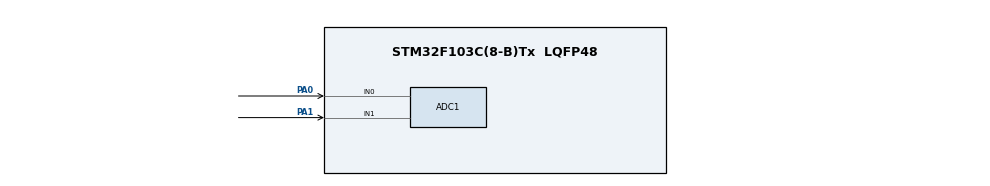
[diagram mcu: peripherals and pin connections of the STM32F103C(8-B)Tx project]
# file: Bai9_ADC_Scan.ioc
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Mcu.Family=STM32F1
NVIC.ADC1_2_IRQn=true\:0\:0\:false\:false\:true\:true\:true
Dma.ADC1.0.Instance=DMA1_Channel1
ADC1.Rank-0\#ChannelRegularConversion=1
ProjectManager.StackSize=0x400
PA0-WKUP.Signal=ADCx_IN0
PA13.Signal=SYS_JTMS-SWDIO
Dma.ADC1.0.PeriphDataAlignment=DMA_PDATAALIGN_HALFWORD
ProjectManager.TargetToolchain=MDK-ARM V5
Dma.ADC1.0.Mode=DMA_CIRCULAR
Dma.ADC1.0.Priority=DMA_PRIORITY_LOW
ADC1.Channel-1\#ChannelRegularConversion=ADC_CHANNEL_1
Dma.ADC1.0.Direction=DMA_PERIPH_TO_MEMORY
Dma.ADC1.0.MemDataAlignment=DMA_MDATAALIGN_HALFWORD
PA1.Signal=ADCx_IN1
ADC1.Channel-0\#ChannelRegularConversion=ADC_CHANNEL_0
board=custom
RCC.APB2Freq_Value=8000000
PA14.Mode=Serial_Wire
Dma.ADC1.0.PeriphInc=DMA_PINC_DISABLE
SH.ADCx_IN0.0=ADC1_IN0,IN0
ADC1.NbrOfConversion=2
PA13.Mode=Serial_Wire
Mcu.Name=STM32F103C(8-B)Tx
ADC1.SamplingTime-0\#ChannelRegularConversion=ADC_SAMPLETIME_239CYCLES_5
ADC1.SamplingTime-1\#ChannelRegularConversion=ADC_SAMPLETIME_239CYCLES_5
Mcu.Package=LQFP48
ADC1.master=1
ADC1.Rank-1\#ChannelRegularConversion=2
PA14.Signal=SYS_JTCK-SWCLK
Dma.ADC1.0.MemInc=DMA_MINC_ENABLE
ProjectManager.HeapSize=0x200
NVIC.PriorityGroup=NVIC_PRIORITYGROUP_4
ADC1.NbrOfConversionFlag=1
SH.ADCx_IN1.0=ADC1_IN1,IN1
NVIC.DMA1_Channel1_IRQn=true\:0\:0\:false\:false\:true\:false\:true
Dma.Request0=ADC1
RCC.APB1Freq_Value=8000000

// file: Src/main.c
/* USER CODE BEGIN Header */
/**
  ******************************************************************************
  * @file           : main.c
  * @brief          : Main program body
  ******************************************************************************
  * @attention
  *
  * <h2><center>&copy; Copyright (c) 2020 STMicroelectronics.
  * All rights reserved.</center></h2>
  *
  * This software component is licensed by ST under BSD 3-Clause license,
  * the "License"; You may not use this file except in compliance with the
  * License. You may obtain a copy of the License at:
  *                        opensource.org/licenses/BSD-3-Clause
  *
  ******************************************************************************
  */
/* USER CODE END Header */

#include "main.h"

ADC_HandleTypeDef hadc1;
DMA_HandleTypeDef hdma_adc1;

void SystemClock_Config(void);
static void MX_GPIO_Init(void);
static void MX_DMA_Init(void);
static void MX_ADC1_Init(void);
/* USER CODE BEGIN PFP */
uint16_t u16_ADCScanVal[2];
  /* NOTE : This function should not be modified. When the callback is needed,
            function HAL_ADC_ConvCpltCallback must be implemented in the user file.
   */
/* USER CODE END PFP */

int main(void)
{

  /* MCU Configuration--------------------------------------------------------*/

  /* Reset of all peripherals, Initializes the Flash interface and the Systick. */
  HAL_Init();

  /* Configure the system clock */
  SystemClock_Config();

  /* Initialize all configured peripherals */
  MX_GPIO_Init();
  MX_DMA_Init();
  MX_ADC1_Init();
  /* USER CODE BEGIN 2 */
	HAL_ADC_Start_DMA(&hadc1, (uint32_t*)u16_ADCScanVal, 2);
  /* USER CODE END 2 */

  /* Infinite loop */
  while (1)
  {

  }
}

void SystemClock_Config(void)
{
  RCC_OscInitTypeDef RCC_OscInitStruct = {0};
  RCC_ClkInitTypeDef RCC_ClkInitStruct = {0};
  RCC_PeriphCLKInitTypeDef PeriphClkInit = {0};

  /** Initializes the CPU, AHB and APB busses clocks
  */
  RCC_OscInitStruct.OscillatorType = RCC_OSCILLATORTYPE_HSI;
  RCC_OscInitStruct.HSIState = RCC_HSI_ON;
  RCC_OscInitStruct.HSICalibrationValue = RCC_HSICALIBRATION_DEFAULT;
  RCC_OscInitStruct.PLL.PLLState = RCC_PLL_NONE;
  if (HAL_RCC_OscConfig(&RCC_OscInitStruct) != HAL_OK)
  {
    Error_Handler();
  }
  /** Initializes the CPU, AHB and APB busses clocks
  */
  RCC_ClkInitStruct.ClockType = RCC_CLOCKTYPE_HCLK|RCC_CLOCKTYPE_SYSCLK
                              |RCC_CLOCKTYPE_PCLK1|RCC_CLOCKTYPE_PCLK2;
  RCC_ClkInitStruct.SYSCLKSource = RCC_SYSCLKSOURCE_HSI;
  RCC_ClkInitStruct.AHBCLKDivider = RCC_SYSCLK_DIV1;
  RCC_ClkInitStruct.APB1CLKDivider = RCC_HCLK_DIV1;
  RCC_ClkInitStruct.APB2CLKDivider = RCC_HCLK_DIV1;

  if (HAL_RCC_ClockConfig(&RCC_ClkInitStruct, FLASH_LATENCY_0) != HAL_OK)
  {
    Error_Handler();
  }
  PeriphClkInit.PeriphClockSelection = RCC_PERIPHCLK_ADC;
  PeriphClkInit.AdcClockSelection = RCC_ADCPCLK2_DIV2;
  if (HAL_RCCEx_PeriphCLKConfig(&PeriphClkInit) != HAL_OK)
  {
    Error_Handler();
  }
}

static void MX_ADC1_Init(void)
{

  ADC_ChannelConfTypeDef sConfig = {0};

  /** Common config
  */
  hadc1.Instance = ADC1;
  hadc1.Init.ScanConvMode = ADC_SCAN_ENABLE;
  hadc1.Init.ContinuousConvMode = ENABLE;
  hadc1.Init.DiscontinuousConvMode = DISABLE;
  hadc1.Init.ExternalTrigConv = ADC_SOFTWARE_START;
  hadc1.Init.DataAlign = ADC_DATAALIGN_RIGHT;
  hadc1.Init.NbrOfConversion = 2;
  if (HAL_ADC_Init(&hadc1) != HAL_OK)
  {
    Error_Handler();
  }
  /** Configure Regular Channel
  */
  sConfig.Channel = ADC_CHANNEL_0;
  sConfig.Rank = ADC_REGULAR_RANK_1;
  sConfig.SamplingTime = ADC_SAMPLETIME_239CYCLES_5;
  if (HAL_ADC_ConfigChannel(&hadc1, &sConfig) != HAL_OK)
  {
    Error_Handler();
  }
  /** Configure Regular Channel
  */
  sConfig.Channel = ADC_CHANNEL_1;
  sConfig.Rank = ADC_REGULAR_RANK_2;
  sConfig.SamplingTime = ADC_SAMPLETIME_1CYCLE_5;
  if (HAL_ADC_ConfigChannel(&hadc1, &sConfig) != HAL_OK)
  {
    Error_Handler();
  }

}

static void MX_DMA_Init(void)
{

  /* DMA controller clock enable */
  __HAL_RCC_DMA1_CLK_ENABLE();

  /* DMA interrupt init */
  /* DMA1_Channel1_IRQn interrupt configuration */
  HAL_NVIC_SetPriority(DMA1_Channel1_IRQn, 0, 0);
  HAL_NVIC_EnableIRQ(DMA1_Channel1_IRQn);

}

static void MX_GPIO_Init(void)
{

  /* GPIO Ports Clock Enable */
  __HAL_RCC_GPIOA_CLK_ENABLE();

}

void Error_Handler(void)
{
}

/************************ (C) COPYRIGHT STMicroelectronics *****END OF FILE****/
